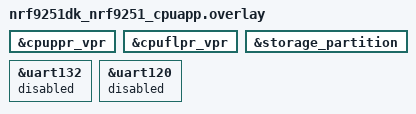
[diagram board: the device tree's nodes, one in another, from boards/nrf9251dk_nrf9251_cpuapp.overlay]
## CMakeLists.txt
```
#
# Copyright (c) 2026 Nordic Semiconductor ASA
#
# SPDX-License-Identifier: LicenseRef-Nordic-5-Clause
#

cmake_minimum_required(VERSION 3.20.0)

find_package(Zephyr REQUIRED HINTS $ENV{ZEPHYR_BASE})
project(mram_concurrent)

zephyr_include_directories(include ${ZEPHYR_BASE})

target_sources(app PRIVATE
  src/main.c
  src/mram_worker.c
)
```

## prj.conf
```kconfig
CONFIG_FLASH=y
CONFIG_FLASH_MAP=y
CONFIG_MPU_ALLOW_FLASH_WRITE=y
CONFIG_ASSERT=y

CONFIG_BOOT_BANNER=n
CONFIG_NCS_BOOT_BANNER=n

CONFIG_DCACHE=n

CONFIG_MRAM_LATENCY=y

# Not needed for the MRAM driver test; incompatible with CONFIG_DCACHE=n.
CONFIG_NRF_MODEM_LIB=n
```

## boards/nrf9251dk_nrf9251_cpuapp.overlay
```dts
/*
 * Copyright (c) 2026 Nordic Semiconductor ASA
 *
 * SPDX-License-Identifier: LicenseRef-Nordic-5-Clause
 */

/* Launch both VPR cores (non-XIP: code copied from MRAM into their TCM). */
&cpuppr_vpr {
	status = "okay";
};

&cpuflpr_vpr {
	status = "okay";
};

&storage_partition {
	status = "okay";
};

&uart132 {
    status = "reserved";
};

&uart120 {
    status = "reserved";
};
```

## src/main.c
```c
/*
 * Copyright (c) 2026 Nordic Semiconductor ASA
 *
 * SPDX-License-Identifier: LicenseRef-Nordic-5-Clause
 */

#include <zephyr/kernel.h>
#include <zephyr/cache.h>
#include <zephyr/devicetree.h>

#if defined(CONFIG_MRAM_LATENCY)
#include <soc/nordic/common/mram_latency.h>
#endif

#include "mram_concurrent.h"

/* Each VPR core reports through a block in its own TCM that cpuapp can read. */
static volatile struct mram_test_status *const ppr_status =
	(struct mram_test_status *)MRAM_PPR_STATUS_ADDR;
static volatile struct mram_test_status *const flpr_status =
	(struct mram_test_status *)MRAM_FLPR_STATUS_ADDR;

static bool remote_passed(volatile struct mram_test_status *st, const char *name, int64_t deadline)
{
	while (k_uptime_get() < deadline) {
		sys_cache_data_invd_range((void *)st, sizeof(*st));
		if (st->ready == MRAM_STATUS_READY && st->done == MRAM_STATUS_DONE) {
			printk("%s: result=%d, longest=%u cycles, errors=%u, iterations=%u\n", name, st->result, st->longest_time, st->errors, st->iterations);
			return (st->result == 0) && (st->iterations > 0);
		}
		k_msleep(50);
	}

	printk("%s: did not finish in time\n", name);
	return false;
}

/* Set define based on if mutexes are defined on the mram1x_controller devicetree node */
#define USING_MRAM_MUTEX DT_NODE_HAS_PROP(DT_NODELABEL(mram1x_controller), nordic_mutexes)

int main(void)
{
	struct mram_test_status app_status;
	bool pass = true;

	//printk("Concurrent MRAM access test on %s\n", CONFIG_BOARD_TARGET);

        printk("\nMRAM latency mode: %s\n", IS_ENABLED(CONFIG_MRAM_LATENCY) ? "enabled" : "disabled");
        printk("MRAMC ready bit check: %s\n", IS_ENABLED(CONFIG_NRF_MRAM_CHECK_READY_BIT) ? "enabled" : "disabled");
        printk("MRAM mutex: %s\n", USING_MRAM_MUTEX ? "enabled" : "disabled");
        printk("MRAM write size = %u, erase size = %u\n", (unsigned int)MRAM_TEST_PATTERN_SIZE, (unsigned int)MRAM_TEST_BLOCK_SIZE);

#if defined(CONFIG_MRAM_LATENCY)
        int rc = mram_no_latency_sync_request();
        if (rc) {
                printk("Failed to request no-latency mode for MRAM write");
                return -EIO;
        }
#endif

	/* cpuapp only reads; cpuppr and cpuflpr write their own patterns. */
	(void)mram_reader_run(&app_status);

	printk("cpuapp: result=%d, longest=%u cycles, errors=%u, iterations=%u\n", app_status.result, app_status.longest_time, app_status.errors, app_status.iterations);
	if (app_status.result != 0 || app_status.iterations == 0) {
		pass = false;
	}

	/* Collect the writer results. */
	int64_t deadline = k_uptime_get() + 5000;

	if (!remote_passed(ppr_status, "cpuppr", deadline)) {
		pass = false;
	}
	if (!remote_passed(flpr_status, "cpuflpr", deadline)) {
		pass = false;
	}

	printk("Tests status: %s\n", pass ? "PASS" : "FAIL");

	return 0;
}
```

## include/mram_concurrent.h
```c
/*
 * Copyright (c) 2026 Nordic Semiconductor ASA
 *
 * SPDX-License-Identifier: LicenseRef-Nordic-5-Clause
 */

#ifndef MRAM_CONCURRENT_H_
#define MRAM_CONCURRENT_H_

#include <string.h>
#include <zephyr/kernel.h>
#include <zephyr/devicetree.h>

/* Duration the writers keep writing and the reader keeps reading. */
#define MRAM_TEST_DURATION_MS 10000

/* MRAM write-block size and the area cpuapp erases up front. */
#define MRAM_TEST_BLOCK_SIZE 4096
#define MRAM_TEST_PATTERN_SIZE 32
#define MRAM_TEST_AREA_SIZE MRAM_TEST_BLOCK_SIZE

/* Per-writer identity mixed into the pattern each writer writes. */
#define MRAM_CORE_PPR  0xB2
#define MRAM_CORE_FLPR 0xC3

/* Each writer owns a distinct area within the storage partition. */
#define MRAM_PPR_AREA_OFFSET  0
#define MRAM_FLPR_AREA_OFFSET MRAM_TEST_BLOCK_SIZE

/* cpuapp uses its own area for the pre-test self write/readback check. */
#define MRAM_APP_AREA_OFFSET (2 * MRAM_TEST_BLOCK_SIZE)

/* Hand-shake magics placed in the shared memory blocks. */
#define MRAM_STATUS_READY 0x52454459 /* "REDY" */
#define MRAM_STATUS_DONE  0x444F4E45 /* "DONE" */
#define MRAM_STATUS_GO	  0x2147474F /* reader released the writers */

/* Writer -> reader (cpuapp) status blocks, in each VPR's TCM. */
#define MRAM_PPR_STATUS_ADDR  DT_REG_ADDR(DT_NODELABEL(cpuppr_cpuapp_ipc_shm))
#define MRAM_FLPR_STATUS_ADDR DT_REG_ADDR(DT_NODELABEL(cpuflpr_cpuapp_ipc_shm))

/* Reader (cpuapp) -> writer control blocks, in each VPR's TCM. */
#define MRAM_PPR_CTRL_ADDR  DT_REG_ADDR(DT_NODELABEL(cpuapp_cpuppr_ipc_shm))
#define MRAM_FLPR_CTRL_ADDR DT_REG_ADDR(DT_NODELABEL(cpuapp_cpuflpr_ipc_shm))

/* Reported by each core through a shared memory block. */
struct mram_test_status {
	volatile uint32_t ready;
	volatile uint32_t done;
	volatile uint32_t iterations;
	volatile int32_t result; /* 0 = pass, negative errno = failure */
	volatile uint32_t longest_time;
	volatile uint32_t errors;
	volatile uint32_t erases; /* writer: times its block was filled and erased */
};

/* cpuapp -> writer release flag. */
struct mram_test_control {
	volatile uint32_t start;
};

static inline void mram_fill_pattern(uint8_t core_id, uint8_t *buf, size_t len)
{
	for (size_t i = 0; i < len; i++) {
		buf[i] = (uint8_t)(core_id ^ (uint8_t)i);
	}
}

/*
 * Writer role (cpuppr / cpuflpr): wait until the reader has erased the area and
 * set @p ctrl->start, then repeatedly write this core's pattern for
 * MRAM_TEST_DURATION_MS. Writes are serialized across cores by the MRAM
 * driver's own hardware mutex.
 *
 * @return 0 on success, negative errno on the first failure.
 */
int mram_writer_run(uint8_t core_id, struct mram_test_status *status,
		    volatile struct mram_test_control *ctrl);

/*
 * Reader role (cpuapp): erase both writer areas, release the writers, then
 * repeatedly read each area for MRAM_TEST_DURATION_MS and verify it holds that
 * writer's pattern (or the erased baseline before the writer has run).
 *
 * @return 0 on success, negative errno on failure.
 */
int mram_reader_run(struct mram_test_status *status);

#endif /* MRAM_CONCURRENT_H_ */
```

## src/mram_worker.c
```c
/*
 * Copyright (c) 2026 Nordic Semiconductor ASA
 *
 * SPDX-License-Identifier: LicenseRef-Nordic-5-Clause
 */

#include <string.h>

#include <zephyr/kernel.h>
#include <zephyr/cache.h>
#include <zephyr/drivers/flash.h>
#include <zephyr/storage/flash_map.h>

#include "mram_concurrent.h"

#define TEST_PARTITION	      storage_partition
#define TEST_PARTITION_OFFSET PARTITION_OFFSET(TEST_PARTITION)
#define TEST_PARTITION_DEVICE PARTITION_DEVICE(TEST_PARTITION)

/* Each writer owns a distinct area within the partition. */
#define PPR_AREA_OFFSET	 (TEST_PARTITION_OFFSET + MRAM_PPR_AREA_OFFSET)
#define FLPR_AREA_OFFSET (TEST_PARTITION_OFFSET + MRAM_FLPR_AREA_OFFSET)
#define APP_AREA_OFFSET	 (TEST_PARTITION_OFFSET + MRAM_APP_AREA_OFFSET)

/* CPU-visible address for a partition offset (same mapping the MRAM driver uses). */
#define MRAM_ABS_ADDR(off) (DT_REG_ADDR(DT_NODELABEL(mram1x)) + (off))

static void print_block(const char *label, const uint8_t *buf, size_t len)
{
	printk("%s:", label);
	for (size_t i = 0; i < len; i++) {
		printk(" %02x", buf[i]);
	}
	printk("\n");
}

int mram_writer_run(uint8_t core_id, struct mram_test_status *status,
		    volatile struct mram_test_control *ctrl)
{
	const struct device *flash_dev = TEST_PARTITION_DEVICE;
	uint8_t pattern[MRAM_TEST_PATTERN_SIZE];
	uint32_t area_offset = (core_id == MRAM_CORE_PPR) ? PPR_AREA_OFFSET : FLPR_AREA_OFFSET;
	int64_t end;
	int err = 0;

	status->ready = 0;
	status->done = 0;
	status->iterations = 0;
	status->result = 0;
        status->longest_time = 0;
        status->errors = 0;
        status->erases = 0;

	const char *core_str = (core_id == MRAM_CORE_PPR) ? "cpuppr" : "cpuflpr";

	if (!device_is_ready(flash_dev)) {
		status->result = -ENODEV;
		status->done = MRAM_STATUS_DONE;
                printk("%s: flash device not ready\n", core_str);
		return -ENODEV;
	}

	mram_fill_pattern(core_id, pattern, sizeof(pattern));

	printk("\n\n%s start: core_id=0x%02x pattern=%u block=%u offset=0x%lx addr=0x%lx\n",
	       core_str, core_id, (unsigned int)sizeof(pattern), (unsigned int)MRAM_TEST_BLOCK_SIZE,
	       (unsigned long)area_offset, (unsigned long)MRAM_ABS_ADDR(area_offset));
	print_block("pattern", pattern, sizeof(pattern));

	status->ready = MRAM_STATUS_READY;

	/* Do not touch the area until the reader has erased it and released us. */
	while (true) {
		sys_cache_data_invd_range((void *)ctrl, sizeof(*ctrl));
		if (ctrl->start == MRAM_STATUS_GO) {
			break;
		}
		k_usleep(100);
	}

        printk("%s writer released by reader\n", core_str);

	end = k_uptime_get() + MRAM_TEST_DURATION_MS;

	uint32_t write_offset = 0;

	while (k_uptime_get() < end) {
		uint32_t write_start = k_cycle_get_32();

		/* Write the 16-byte pattern into the next slot of this core's block. */
		err = flash_write(flash_dev, area_offset + write_offset, pattern, sizeof(pattern));

		uint32_t write_time = k_cycle_get_32() - write_start;

		if (write_time > status->longest_time) {
			status->longest_time = write_time;
		}
		if (err) {
			status->errors++;
		}

		write_offset += MRAM_TEST_PATTERN_SIZE;
		if (write_offset >= MRAM_TEST_BLOCK_SIZE) {
			/* Last slot written: erase the block and count the wrap. */
			err = flash_erase(flash_dev, area_offset, MRAM_TEST_AREA_SIZE);
			if (err) {
				status->errors++;
			}
			status->erases++;
			write_offset = 0;
		}

		status->iterations++;

		/* Yield so the slower writer is not starved of MRAM access. */
		k_usleep(100);
	}

	/* Read back the final contents once writing has stopped. */
	uint8_t final_read[MRAM_TEST_PATTERN_SIZE];
	int read_err = flash_read(flash_dev, area_offset, final_read, sizeof(final_read));

	if (read_err == 0) {
		print_block("final read", final_read, sizeof(final_read));
	} else {
		printk("%s final read failed: %d\n", core_str, read_err);
	}

	status->result = err;
	status->done = MRAM_STATUS_DONE;

	return err;
}

int mram_reader_run(struct mram_test_status *status)
{
	const struct device *flash_dev = TEST_PARTITION_DEVICE;
	volatile struct mram_test_control *ppr_ctrl =
		(struct mram_test_control *)MRAM_PPR_CTRL_ADDR;
	volatile struct mram_test_control *flpr_ctrl =
		(struct mram_test_control *)MRAM_FLPR_CTRL_ADDR;
	uint8_t ppr_pattern[MRAM_TEST_PATTERN_SIZE];
	uint8_t flpr_pattern[MRAM_TEST_PATTERN_SIZE];
	uint8_t erased[MRAM_TEST_PATTERN_SIZE];
	uint8_t readback[MRAM_TEST_PATTERN_SIZE];
	int64_t end;
	int err = 0;

	status->ready = 0;
	status->done = 0;
	status->iterations = 0;
	status->result = 0;
	status->longest_time = 0;
        status->errors = 0;

	if (!device_is_ready(flash_dev)) {
                printk("cpuapp: flash device not ready\n");
		status->result = -ENODEV;
		status->done = MRAM_STATUS_DONE;
		return -ENODEV;
	}

	mram_fill_pattern(MRAM_CORE_PPR, ppr_pattern, sizeof(ppr_pattern));
	mram_fill_pattern(MRAM_CORE_FLPR, flpr_pattern, sizeof(flpr_pattern));
	memset(erased, 0xff, sizeof(erased));

	/* The writers own and auto-erase their areas, so cpuapp must NOT erase
	 * them here: cpuapp's cached erase can return before the MRAMC finishes,
	 * and the VPR's immediate write to that page then stalls the bus.
	 */

	/* Sanity-check cpuapp's own MRAM write/readback (separate area) before
	 * releasing the writers.
	 */
	uint8_t self_pattern[MRAM_TEST_PATTERN_SIZE];

	mram_fill_pattern(0xA5, self_pattern, sizeof(self_pattern));
	err = flash_write(flash_dev, APP_AREA_OFFSET, self_pattern, sizeof(self_pattern));
	if (err == 0) {
		err = flash_read(flash_dev, APP_AREA_OFFSET, readback, sizeof(readback));
	}
	if (err) {
		printk("cpuapp: self write/read failed: %d\n", err);
		status->result = err;
		status->done = MRAM_STATUS_DONE;
		return err;
	}
	if (memcmp(readback, self_pattern, sizeof(self_pattern)) != 0) {
		printk("cpuapp: self write/readback mismatch\n");
		print_block("wrote", self_pattern, sizeof(self_pattern));
		print_block("read ", readback, sizeof(readback));
		status->result = -EIO;
		status->done = MRAM_STATUS_DONE;
		return -EIO;
	}

	/* Release the writers now that the baseline is in place. */
	ppr_ctrl->start = MRAM_STATUS_GO;
	flpr_ctrl->start = MRAM_STATUS_GO;
	sys_cache_data_flush_range((void *)ppr_ctrl, sizeof(*ppr_ctrl));
	sys_cache_data_flush_range((void *)flpr_ctrl, sizeof(*flpr_ctrl));

	status->ready = MRAM_STATUS_READY;

	end = k_uptime_get() + MRAM_TEST_DURATION_MS;

	while (k_uptime_get() < end && err == 0) {
                uint32_t read_start = k_cycle_get_32();

                err = flash_read(flash_dev, APP_AREA_OFFSET, self_pattern, sizeof(self_pattern));

                uint32_t read_time = k_cycle_get_32() - read_start;

                if (read_time > status->longest_time) {
                        status->longest_time = read_time;
                }
                status->iterations++;

                if (err) {
                        status->errors++;
                }

		k_usleep(500);
	}

	status->result = err;
	status->done = MRAM_STATUS_DONE;

	return err;
}
```
